# CY8C5488AXI_LP120 register map
File version: 0.1
Registers are 8-bit, read-write, no defined reset value unless marked. A register's access mark holds for its fields unless they carry their own. Offsets are from the block's base; [hi:lo] are bit positions; 'fields as' and 'values as' point back to an identical list.

## HC_REG
Base 0x40006478
0x00 HC_REG_CONTROL_REG

## IR_REG
Base 0x40006577
Registers as HC_REG (with HC_REG read as IR_REG).

## LCD_Cntl_Port
Base 0x40006476
Registers as HC_REG (with HC_REG read as LCD_Cntl_Port).

## HC_Timer_S
Base 0x00000000
0x40006408 HC_Timer_S_COUNTER 16-bit — UDB.A0 - Current Down Counter Value
0x40006428 HC_Timer_S_PERIOD 16-bit — UDB.D0 - Assigned Period
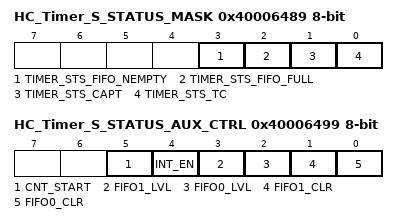
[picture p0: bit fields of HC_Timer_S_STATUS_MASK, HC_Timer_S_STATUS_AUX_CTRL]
0x40006489 HC_Timer_S_STATUS_MASK — UDB Status bits Interrupt Mask Enable Register
  [3] TIMER_STS_FIFO_NEMPTY ro — FIFO Empty status
  [2] TIMER_STS_FIFO_FULL ro — FIFO Full Status
  [1] TIMER_STS_CAPT ro — Enables the Interrupt on Capture
  [0] TIMER_STS_TC ro — Enables the Interrupt on TC
0x40006499 HC_Timer_S_STATUS_AUX_CTRL — UDB Auxilliary Control Register
  [5] CNT_START — FIFO0 clear
    0=E_CNT_START0 (Disable counter); 1=E_CNT_START1 (Enable counter)
  [4] INT_EN
    0=E_INT_EN0 (Interrupt disabled); 1=E_INT_EN1 (Interrupt enabled)
  [3] FIFO1_LVL — FIFO level
    0=E_FIFO_LVL_0 (FIFO LVL: input mode: FIFO not full; output mode: FIFO not empty); 1=E_FIFO_LVL_1 (FIFO LVL: input mode: FIFO at least 1/2 empty; output mode: FIFO at least 1/2 full)
  [2] FIFO0_LVL — FIFO level
    values as FIFO1_LVL
  [1] FIFO1_CLR — FIFO1 clear
    0=E_FIFO_CLR_0 (Normal FIFO operation); 1=E_FIFO_CLR_1 (Clear FIFO state)
  [0] FIFO0_CLR — FIFO0 clear
    values as FIFO1_CLR

## BEAM_BREAK_TIMER
Base 0x00000000
0x40006404 BEAM_BREAK_TIMER_COUNTER 16-bit — UDB.A0 - Current Down Counter Value
0x40006424 BEAM_BREAK_TIMER_PERIOD 16-bit — UDB.D0 - Assigned Period
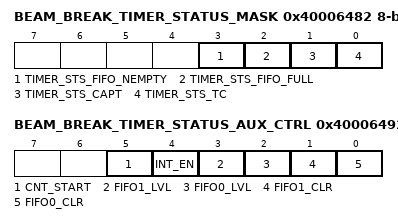
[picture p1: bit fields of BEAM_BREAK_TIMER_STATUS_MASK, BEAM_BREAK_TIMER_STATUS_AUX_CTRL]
0x40006482 BEAM_BREAK_TIMER_STATUS_MASK — UDB Status bits Interrupt Mask Enable Register
  [3] TIMER_STS_FIFO_NEMPTY ro — FIFO Empty status
  [2] TIMER_STS_FIFO_FULL ro — FIFO Full Status
  [1] TIMER_STS_CAPT ro — Enables the Interrupt on Capture
  [0] TIMER_STS_TC ro — Enables the Interrupt on TC
0x40006492 BEAM_BREAK_TIMER_STATUS_AUX_CTRL — UDB Auxilliary Control Register
  [5] CNT_START — FIFO0 clear
    0=E_CNT_START0 (Disable counter); 1=E_CNT_START1 (Enable counter)
  [4] INT_EN
    0=E_INT_EN0 (Interrupt disabled); 1=E_INT_EN1 (Interrupt enabled)
  [3] FIFO1_LVL — FIFO level
    0=E_FIFO_LVL_0 (FIFO LVL: input mode: FIFO not full; output mode: FIFO not empty); 1=E_FIFO_LVL_1 (FIFO LVL: input mode: FIFO at least 1/2 empty; output mode: FIFO at least 1/2 full)
  [2] FIFO0_LVL — FIFO level
    values as FIFO1_LVL
  [1] FIFO1_CLR — FIFO1 clear
    0=E_FIFO_CLR_0 (Normal FIFO operation); 1=E_FIFO_CLR_1 (Clear FIFO state)
  [0] FIFO0_CLR — FIFO0 clear
    values as FIFO1_CLR

## Timer
Base 0x00000000
0x4000640A Timer_COUNTER 24-bit — UDB.A0 - Current Down Counter Value
0x4000642A Timer_PERIOD 24-bit — UDB.D0 - Assigned Period
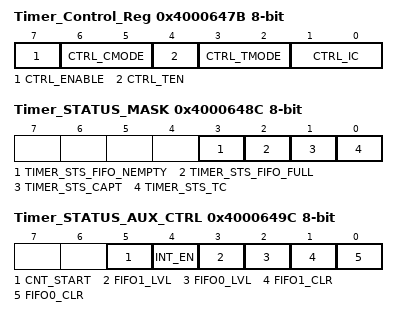
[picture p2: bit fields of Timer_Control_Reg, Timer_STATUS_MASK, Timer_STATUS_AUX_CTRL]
0x4000647B Timer_Control_Reg — UDB Control Register - Assigned Control Register Value
  [7] CTRL_ENABLE — Enable the Timer
  [6:5] CTRL_CMODE — Capture Mode
  [4] CTRL_TEN — Trigger Enable Bit
  [3:2] CTRL_TMODE — Trigger Mode
  [1:0] CTRL_IC — Interrupt Count
0x4000648C Timer_STATUS_MASK — UDB Status bits Interrupt Mask Enable Register
  [3] TIMER_STS_FIFO_NEMPTY ro — FIFO Empty status
  [2] TIMER_STS_FIFO_FULL ro — FIFO Full Status
  [1] TIMER_STS_CAPT ro — Enables the Interrupt on Capture
  [0] TIMER_STS_TC ro — Enables the Interrupt on TC
0x4000649C Timer_STATUS_AUX_CTRL — UDB Auxilliary Control Register
  [5] CNT_START — FIFO0 clear
    0=E_CNT_START0 (Disable counter); 1=E_CNT_START1 (Enable counter)
  [4] INT_EN
    0=E_INT_EN0 (Interrupt disabled); 1=E_INT_EN1 (Interrupt enabled)
  [3] FIFO1_LVL — FIFO level
    0=E_FIFO_LVL_0 (FIFO LVL: input mode: FIFO not full; output mode: FIFO not empty); 1=E_FIFO_LVL_1 (FIFO LVL: input mode: FIFO at least 1/2 empty; output mode: FIFO at least 1/2 full)
  [2] FIFO0_LVL — FIFO level
    values as FIFO1_LVL
  [1] FIFO1_CLR — FIFO1 clear
    0=E_FIFO_CLR_0 (Normal FIFO operation); 1=E_FIFO_CLR_1 (Clear FIFO state)
  [0] FIFO0_CLR — FIFO0 clear
    values as FIFO1_CLR
